# STM32WBA23 register map
File version: 1.0
CPU: CM33 r0p1, little endian, MPU, FPU, 4 interrupt priority bits
Registers are 32-bit, read-write, reset 0x0 unless marked. A register's access mark holds for its fields unless they carry their own. Offsets are from the block's base; [hi:lo] are bit positions; {n}, {i} and the like mark numbered series.

## GPIOB — GPIOB address block description
Base 0x42020400
Same registers: SEC_GPIOB 0x52020400
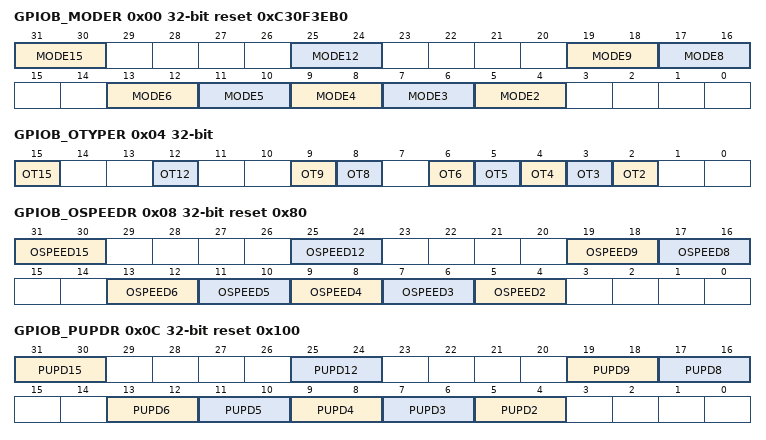
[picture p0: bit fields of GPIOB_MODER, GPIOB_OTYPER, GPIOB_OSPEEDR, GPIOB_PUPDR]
0x00 GPIOB_MODER reset 0xC30F3EB0 — GPIO port B mode register
  [31:30] MODE15 — Port configuration I/O pin 15
    0=Input mode; 1=General purpose output mode; 2=Alternate function mode; 3=Analog mode (reset state)
  [25:24] MODE12 — Port configuration I/O pin 12
  [19:18] MODE9 — Port configuration I/O pin 9
  [17:16] MODE8 — Port configuration I/O pin 8
  [2n+1:2n] MODE{n} (n=2..6) — Port configuration I/O pin {n}
0x04 GPIOB_OTYPER — GPIO port B output type register
  [15] OT15
  [12] OT12
  [9] OT9 — OT[9:8: Port configuration I/O pin y
  [8] OT8 — OT[9:8: Port configuration I/O pin y
  [n] OT{n} (n=2..6) — Port configuration I/O pin y
0x08 GPIOB_OSPEEDR reset 0x80 — GPIO port B output speed register
  [31:30] OSPEED15 — Port configuration I/O pin 15
    0=Low speed; 1=Medium speed; 2=High speed
  [25:24] OSPEED12 — Port configuration I/O pin 12
  [19:18] OSPEED9 — Port configuration I/O pin 9
  [17:16] OSPEED8 — Port configuration I/O pin 8
  [2n+1:2n] OSPEED{n} (n=2..6) — Port configuration I/O pin {n}
0x0C GPIOB_PUPDR reset 0x100 — GPIO port B pull-up/pull-down register
  [31:30] PUPD15 — Port configuration I/O pin 15
    0=No pull-up, pull-down; 1=Pull-up; 2=Pull-down
  [25:24] PUPD12 — Port configuration I/O pin 12
  [19:18] PUPD9 — Port configuration I/O pin 9
  [17:16] PUPD8 — Port configuration I/O pin 8
  [2n+1:2n] PUPD{n} (n=2..6) — Port configuration I/O pin {n}
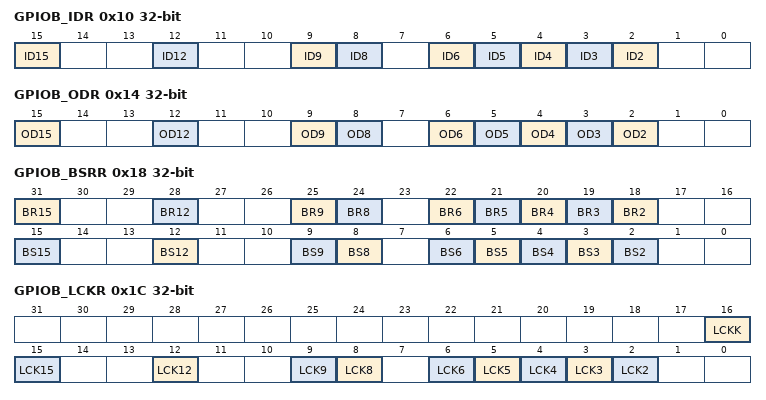
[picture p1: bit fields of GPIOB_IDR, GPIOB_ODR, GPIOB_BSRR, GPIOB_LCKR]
0x10 GPIOB_IDR ro (reset mask 0xFFFF0000) — GPIO port B input data register
  [15] ID15
  [12] ID12
  [9] ID9 — Port input data I/O pin y
  [8] ID8 — Port input data I/O pin y
  [n] ID{n} (n=2..6) — Port input data I/O pin y
0x14 GPIOB_ODR — GPIO port B output data register
  [15] OD15
  [12] OD12
  [9] OD9 — Port output data I/O pin y
  [8] OD8 — Port output data I/O pin y
  [n] OD{n} (n=2..6) — Port output data I/O pin y
0x18 GPIOB_BSRR wo — GPIO port B bit set/reset register
  [31] BR15
  [28] BR12
  [25] BR9 — Port reset I/O pin y
  [24] BR8 — Port reset I/O pin y
  [n+16] BR{n} (n=2..6) — Port reset I/O pin y
  [15] BS15
  [12] BS12
  [9] BS9 — Port set I/O pin y
  [8] BS8 — Port set I/O pin y
  [n] BS{n} (n=2..6) — Port set I/O pin y
0x1C GPIOB_LCKR — GPIO port B configuration lock register
  [16] LCKK — Lock key
    0=Port configuration lock key not active; 1=Port configuration lock key active
  [15] LCK15
  [12] LCK12
  [9] LCK9 — Port lock I/O pin y
  [8] LCK8 — Port lock I/O pin y
  [n] LCK{n} (n=2..6) — Port lock I/O pin y
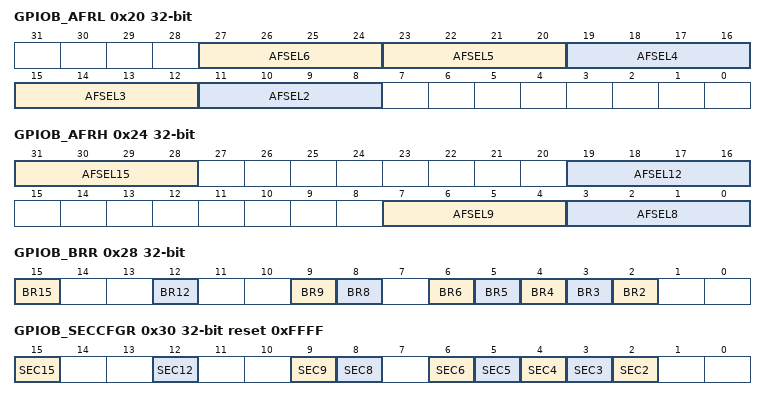
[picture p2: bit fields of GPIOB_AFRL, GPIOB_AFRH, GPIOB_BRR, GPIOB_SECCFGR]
0x20 GPIOB_AFRL — GPIO port B alternate function low register
  [27:24] AFSEL6 — Alternate function selection for port I/O pin 6
    {v}=AF{v} (v=0..15)
  [4n+3:4n] AFSEL{n} (n=2..5) — Alternate function selection for port I/O pin {n}
0x24 GPIOB_AFRH — GPIO port B alternate function high register
  [31:28] AFSEL15 — Alternate function selection for port I/O pin 15
    {v}=AF{v} (v=0..15)
  [19:16] AFSEL12 — Alternate function selection for port I/O pin 12
  [7:4] AFSEL9 — Alternate function selection for port I/O pin 9
  [3:0] AFSEL8 — Alternate function selection for port I/O pin 8
0x28 GPIOB_BRR wo — GPIO port B bit reset register
  [15] BR15
  [12] BR12
  [9] BR9 — Port reset I/O pin y
  [8] BR8 — Port reset I/O pin y
  [n] BR{n} (n=2..6) — Port reset I/O pin y
0x30 GPIOB_SECCFGR wo reset 0xFFFF — GPIO port B secure configuration register
  [15] SEC15
  [12] SEC12
  [9] SEC9 — I/O pin of port secure bit enable y
    0=The I/O pin is non-secure; 1=The I/O pin is secure
  [8] SEC8 — I/O pin of port secure bit enable y
    0=The I/O pin is non-secure; 1=The I/O pin is secure
  [n] SEC{n} (n=2..6) — I/O pin of port secure bit enable y
    0=The I/O pin is non-secure; 1=The I/O pin is secure
